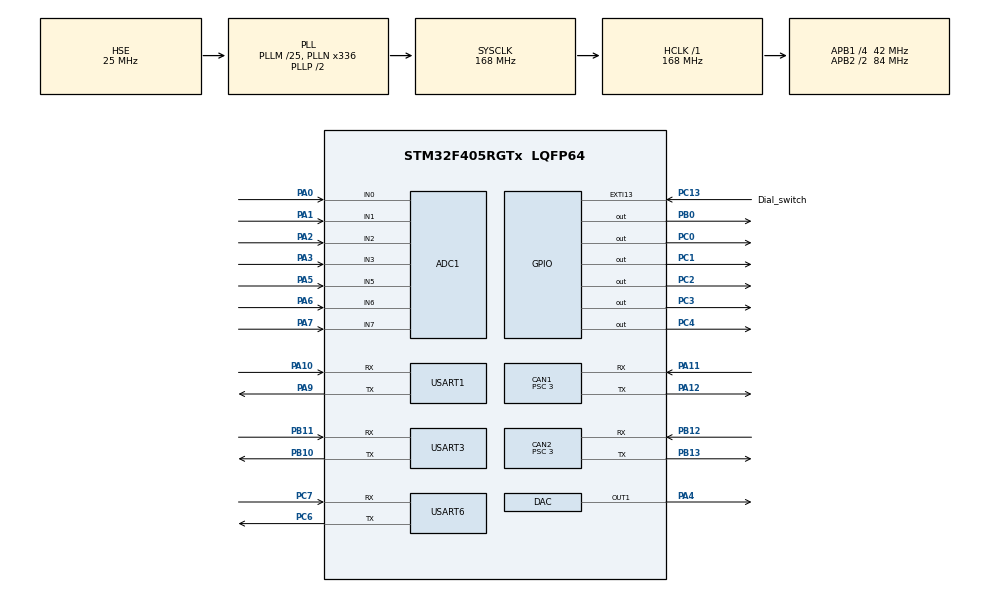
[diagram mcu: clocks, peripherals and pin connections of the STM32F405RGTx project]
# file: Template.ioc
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ADC1.Channel-0\#ChannelRegularConversion=ADC_CHANNEL_0
ADC1.Channel-1\#ChannelRegularConversion=ADC_CHANNEL_1
ADC1.Channel-2\#ChannelRegularConversion=ADC_CHANNEL_2
ADC1.Channel-3\#ChannelRegularConversion=ADC_CHANNEL_3
ADC1.Channel-4\#ChannelRegularConversion=ADC_CHANNEL_5
ADC1.Channel-5\#ChannelRegularConversion=ADC_CHANNEL_6
ADC1.Channel-6\#ChannelRegularConversion=ADC_CHANNEL_7
ADC1.ContinuousConvMode=ENABLE
ADC1.DMAContinuousRequests=ENABLE
ADC1.NbrOfConversion=7
ADC1.NbrOfConversionFlag=1
ADC1.Rank-0\#ChannelRegularConversion=1
ADC1.Rank-1\#ChannelRegularConversion=2
ADC1.Rank-2\#ChannelRegularConversion=3
ADC1.Rank-3\#ChannelRegularConversion=4
ADC1.Rank-4\#ChannelRegularConversion=5
ADC1.Rank-5\#ChannelRegularConversion=6
ADC1.Rank-6\#ChannelRegularConversion=7
ADC1.SamplingTime-0\#ChannelRegularConversion=ADC_SAMPLETIME_3CYCLES
ADC1.SamplingTime-1\#ChannelRegularConversion=ADC_SAMPLETIME_3CYCLES
ADC1.SamplingTime-2\#ChannelRegularConversion=ADC_SAMPLETIME_3CYCLES
ADC1.SamplingTime-3\#ChannelRegularConversion=ADC_SAMPLETIME_3CYCLES
ADC1.SamplingTime-4\#ChannelRegularConversion=ADC_SAMPLETIME_3CYCLES
ADC1.SamplingTime-5\#ChannelRegularConversion=ADC_SAMPLETIME_3CYCLES
ADC1.SamplingTime-6\#ChannelRegularConversion=ADC_SAMPLETIME_3CYCLES
ADC1.ScanConvMode=ENABLE
ADC1.master=1
CAN1.ABOM=ENABLE
CAN1.BS1=CAN_BS1_9TQ
CAN1.BS2=CAN_BS2_4TQ
CAN1.CalculateTimeQuantum=71.42857142857143
CAN1.NART=ENABLE
CAN1.Prescaler=3
CAN2.ABOM=ENABLE
CAN2.BS1=CAN_BS1_9TQ
CAN2.BS2=CAN_BS2_4TQ
CAN2.CalculateTimeQuantum=71.42857142857143
CAN2.NART=ENABLE
CAN2.Prescaler=3
DAC.DAC_OutputBuffer=DAC_OUTPUTBUFFER_DISABLE
Dma.ADC1.6.Direction=DMA_PERIPH_TO_MEMORY
Dma.ADC1.6.FIFOMode=DMA_FIFOMODE_DISABLE
Dma.ADC1.6.Instance=DMA2_Stream0
Dma.ADC1.6.MemDataAlignment=DMA_MDATAALIGN_WORD
Dma.ADC1.6.MemInc=DMA_MINC_ENABLE
Dma.ADC1.6.Mode=DMA_CIRCULAR
Dma.ADC1.6.PeriphDataAlignment=DMA_PDATAALIGN_WORD
Dma.ADC1.6.PeriphInc=DMA_PINC_DISABLE
Dma.ADC1.6.Priority=DMA_PRIORITY_HIGH
Dma.DAC1.7.Direction=DMA_MEMORY_TO_PERIPH
Dma.DAC1.7.FIFOMode=DMA_FIFOMODE_DISABLE
Dma.DAC1.7.Instance=DMA1_Stream5
Dma.DAC1.7.MemDataAlignment=DMA_MDATAALIGN_HALFWORD
Dma.DAC1.7.MemInc=DMA_MINC_ENABLE
Dma.DAC1.7.Mode=DMA_NORMAL
Dma.DAC1.7.PeriphDataAlignment=DMA_PDATAALIGN_HALFWORD
Dma.DAC1.7.PeriphInc=DMA_PINC_DISABLE
Dma.DAC1.7.Priority=DMA_PRIORITY_HIGH
Dma.Request0=USART1_RX
Dma.Request1=USART1_TX
Dma.Request2=USART3_RX
Dma.Request3=USART3_TX
Dma.Request4=USART6_RX
Dma.Request5=USART6_TX
Dma.Request6=ADC1
Dma.Request7=DAC1
Dma.USART1_RX.0.Direction=DMA_PERIPH_TO_MEMORY
Dma.USART1_RX.0.FIFOMode=DMA_FIFOMODE_DISABLE
Dma.USART1_RX.0.Instance=DMA2_Stream2
Dma.USART1_RX.0.MemDataAlignment=DMA_MDATAALIGN_BYTE
Dma.USART1_RX.0.MemInc=DMA_MINC_ENABLE
Dma.USART1_RX.0.Mode=DMA_NORMAL
Dma.USART1_RX.0.PeriphDataAlignment=DMA_PDATAALIGN_BYTE
Dma.USART1_RX.0.PeriphInc=DMA_PINC_DISABLE
Dma.USART1_RX.0.Priority=DMA_PRIORITY_LOW
Dma.USART1_TX.1.Direction=DMA_MEMORY_TO_PERIPH
Dma.USART1_TX.1.FIFOMode=DMA_FIFOMODE_DISABLE
Dma.USART1_TX.1.Instance=DMA2_Stream7
Dma.USART1_TX.1.MemDataAlignment=DMA_MDATAALIGN_BYTE
Dma.USART1_TX.1.MemInc=DMA_MINC_ENABLE
Dma.USART1_TX.1.Mode=DMA_NORMAL
Dma.USART1_TX.1.PeriphDataAlignment=DMA_PDATAALIGN_BYTE
Dma.USART1_TX.1.PeriphInc=DMA_PINC_DISABLE
Dma.USART1_TX.1.Priority=DMA_PRIORITY_LOW
Dma.USART3_RX.2.Direction=DMA_PERIPH_TO_MEMORY
Dma.USART3_RX.2.FIFOMode=DMA_FIFOMODE_DISABLE
Dma.USART3_RX.2.Instance=DMA1_Stream1
Dma.USART3_RX.2.MemDataAlignment=DMA_MDATAALIGN_BYTE
Dma.USART3_RX.2.MemInc=DMA_MINC_ENABLE
Dma.USART3_RX.2.Mode=DMA_NORMAL
Dma.USART3_RX.2.PeriphDataAlignment=DMA_PDATAALIGN_BYTE
Dma.USART3_RX.2.PeriphInc=DMA_PINC_DISABLE
Dma.USART3_RX.2.Priority=DMA_PRIORITY_LOW
Dma.USART3_TX.3.Direction=DMA_MEMORY_TO_PERIPH
Dma.USART3_TX.3.FIFOMode=DMA_FIFOMODE_DISABLE
Dma.USART3_TX.3.Instance=DMA1_Stream3
Dma.USART3_TX.3.MemDataAlignment=DMA_MDATAALIGN_BYTE
Dma.USART3_TX.3.MemInc=DMA_MINC_ENABLE
Dma.USART3_TX.3.Mode=DMA_NORMAL
Dma.USART3_TX.3.PeriphDataAlignment=DMA_PDATAALIGN_BYTE
Dma.USART3_TX.3.PeriphInc=DMA_PINC_DISABLE
Dma.USART3_TX.3.Priority=DMA_PRIORITY_LOW
Dma.USART6_RX.4.Direction=DMA_PERIPH_TO_MEMORY
Dma.USART6_RX.4.FIFOMode=DMA_FIFOMODE_DISABLE
Dma.USART6_RX.4.Instance=DMA2_Stream1
Dma.USART6_RX.4.MemDataAlignment=DMA_MDATAALIGN_BYTE
Dma.USART6_RX.4.MemInc=DMA_MINC_ENABLE
Dma.USART6_RX.4.Mode=DMA_NORMAL
Dma.USART6_RX.4.PeriphDataAlignment=DMA_PDATAALIGN_BYTE
Dma.USART6_RX.4.PeriphInc=DMA_PINC_DISABLE
Dma.USART6_RX.4.Priority=DMA_PRIORITY_LOW
Dma.USART6_TX.5.Direction=DMA_MEMORY_TO_PERIPH
Dma.USART6_TX.5.FIFOMode=DMA_FIFOMODE_DISABLE
Dma.USART6_TX.5.Instance=DMA2_Stream6
Dma.USART6_TX.5.MemDataAlignment=DMA_MDATAALIGN_BYTE
Dma.USART6_TX.5.MemInc=DMA_MINC_ENABLE
Dma.USART6_TX.5.Mode=DMA_NORMAL
Dma.USART6_TX.5.PeriphDataAlignment=DMA_PDATAALIGN_BYTE
Dma.USART6_TX.5.PeriphInc=DMA_PINC_DISABLE
Dma.USART6_TX.5.Priority=DMA_PRIORITY_LOW
FREERTOS.INCLUDE_vTaskDelayUntil=1
FREERTOS.Tasks01=defaultTask,0,128,StartDefaultTask,Default,NULL
Mcu.Family=STM32F4
Mcu.Name=STM32F405RGTx
Mcu.Package=LQFP64
NVIC.ADC_IRQn=true\:5\:0\:false\:false\:true\:true\:true\:true
NVIC.CAN1_RX0_IRQn=true\:5\:0\:false\:false\:true\:true\:true\:true
NVIC.CAN1_RX1_IRQn=true\:5\:0\:false\:false\:true\:true\:true\:true
NVIC.CAN2_RX0_IRQn=true\:5\:0\:false\:false\:true\:true\:true\:true
NVIC.CAN2_RX1_IRQn=true\:5\:0\:false\:false\:true\:true\:true\:true
NVIC.CAN2_SCE_IRQn=true\:5\:0\:false\:false\:true\:true\:true\:true
NVIC.CAN2_TX_IRQn=true\:5\:0\:false\:false\:true\:true\:true\:true
NVIC.DMA1_Stream1_IRQn=true\:5\:0\:false\:false\:true\:true\:false\:true
NVIC.DMA1_Stream3_IRQn=true\:5\:0\:false\:false\:true\:true\:false\:true
NVIC.DMA1_Stream5_IRQn=true\:5\:0\:false\:false\:true\:true\:false\:true
NVIC.DMA2_Stream0_IRQn=true\:5\:0\:false\:false\:true\:true\:false\:true
NVIC.DMA2_Stream1_IRQn=true\:5\:0\:false\:false\:true\:true\:false\:true
NVIC.DMA2_Stream2_IRQn=true\:5\:0\:false\:false\:true\:true\:false\:true
NVIC.DMA2_Stream6_IRQn=true\:5\:0\:false\:false\:true\:true\:false\:true
NVIC.DMA2_Stream7_IRQn=true\:5\:0\:false\:false\:true\:true\:false\:true
NVIC.EXTI15_10_IRQn=true\:5\:0\:false\:false\:true\:true\:true\:true
NVIC.PriorityGroup=NVIC_PRIORITYGROUP_4
NVIC.TIM4_IRQn=true\:5\:0\:false\:false\:true\:true\:true\:true
NVIC.TIM5_IRQn=true\:0\:0\:false\:false\:true\:false\:false\:true
NVIC.TIM6_DAC_IRQn=true\:5\:0\:false\:false\:true\:true\:true\:true
NVIC.TimeBase=TIM5_IRQn
NVIC.TimeBaseIP=TIM5
NVIC.USART1_IRQn=true\:5\:0\:false\:false\:true\:true\:true\:true
NVIC.USART6_IRQn=true\:5\:0\:false\:false\:true\:true\:true\:true
PA0-WKUP.Signal=ADCx_IN0
PA1.Signal=ADCx_IN1
PA10.Mode=Asynchronous
PA10.Signal=USART1_RX
PA11.Mode=Master
PA11.Signal=CAN1_RX
PA12.Mode=Master
PA12.Signal=CAN1_TX
PA13.Mode=Serial_Wire
PA13.Signal=SYS_JTMS-SWDIO
PA14.Mode=Serial_Wire
PA14.Signal=SYS_JTCK-SWCLK
PA2.Signal=ADCx_IN2
PA3.Signal=ADCx_IN3
PA4.Signal=COMP_DAC1_group
PA5.Signal=ADCx_IN5
PA6.Signal=ADCx_IN6
PA7.Signal=ADCx_IN7
PA9.Mode=Asynchronous
PA9.Signal=USART1_TX
PB0.GPIO_ModeDefaultOutputPP=GPIO_MODE_OUTPUT_OD
PB0.PinState=GPIO_PIN_RESET
PB0.Signal=GPIO_Output
PB10.Mode=Asynchronous
PB10.Signal=USART3_TX
PB11.Mode=Asynchronous
PB11.Signal=USART3_RX
PB12.Mode=Slave
PB12.Signal=CAN2_RX
PB13.Mode=Slave
PB13.Signal=CAN2_TX
PC0.GPIO_Speed=GPIO_SPEED_FREQ_HIGH
PC0.PinState=GPIO_PIN_RESET
PC0.Signal=GPIO_Output
PC1.GPIO_Speed=GPIO_SPEED_FREQ_HIGH
PC1.Signal=GPIO_Output
PC13-ANTI_TAMP.GPIO_Label=Dial_switch
PC13-ANTI_TAMP.GPIO_ModeDefaultEXTI=GPIO_MODE_IT_FALLING
PC13-ANTI_TAMP.GPIO_PuPd=GPIO_PULLUP
PC13-ANTI_TAMP.Signal=GPXTI13
PC2.GPIO_Speed=GPIO_SPEED_FREQ_HIGH
PC2.Signal=GPIO_Output
PC3.GPIO_Speed=GPIO_SPEED_FREQ_HIGH
PC3.Signal=GPIO_Output
PC4.GPIO_Speed=GPIO_SPEED_FREQ_HIGH
PC4.Signal=GPIO_Output
PC6.Mode=Asynchronous
PC6.Signal=USART6_TX
PC7.Mode=Asynchronous
PC7.Signal=USART6_RX
PH0-OSC_IN.Mode=HSE-External-Oscillator
PH0-OSC_IN.Signal=RCC_OSC_IN
PH1-OSC_OUT.Mode=HSE-External-Oscillator
PH1-OSC_OUT.Signal=RCC_OSC_OUT
ProjectManager.HeapSize=0x200
ProjectManager.StackSize=0x400
ProjectManager.TargetToolchain=MDK-ARM V5.27
RCC.48MHZClocksFreq_Value=84000000
RCC.AHBFreq_Value=168000000
RCC.APB1CLKDivider=RCC_HCLK_DIV4
RCC.APB1Freq_Value=42000000
RCC.APB1TimFreq_Value=84000000
RCC.APB2CLKDivider=RCC_HCLK_DIV2
RCC.APB2Freq_Value=84000000
RCC.APB2TimFreq_Value=168000000
RCC.CortexFreq_Value=168000000
RCC.HCLKFreq_Value=168000000
RCC.HSE_VALUE=25000000
RCC.HSI_VALUE=16000000
RCC.LSE_VALUE=32768
RCC.PLLM=25
RCC.PLLN=336
RCC.PLLSourceVirtual=RCC_PLLSOURCE_HSE
RCC.SYSCLKFreq_VALUE=168000000
RCC.SYSCLKSource=RCC_SYSCLKSOURCE_PLLCLK
RCC.VCOOutputFreq_Value=336000000
SH.ADCx_IN0.0=ADC1_IN0,IN0
SH.ADCx_IN1.0=ADC1_IN1,IN1
SH.ADCx_IN2.0=ADC1_IN2,IN2
SH.ADCx_IN3.0=ADC1_IN3,IN3
SH.ADCx_IN5.0=ADC1_IN5,IN5
SH.ADCx_IN6.0=ADC1_IN6,IN6
SH.ADCx_IN7.0=ADC1_IN7,IN7
SH.COMP_DAC1_group.0=DAC_OUT1,DAC_OUT1
TIM4.Period=65535
TIM4.Prescaler=83
USART1.VirtualMode=VM_ASYNC
USART3.VirtualMode=VM_ASYNC
USART6.VirtualMode=VM_ASYNC
VP_FREERTOS_VS_CMSIS_V1.Mode=CMSIS_V1
VP_SYS_VS_tim5.Mode=TIM5
VP_TIM4_VS_ClockSourceINT.Mode=Internal
board=custom

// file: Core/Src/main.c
/* USER CODE BEGIN Header */
/**
  ******************************************************************************
  * @file           : main.c
  * @brief          : Main program body
  ******************************************************************************
  * @attention
  *
  * <h2><center>&copy; Copyright (c) 2019 STMicroelectronics.
  * All rights reserved.</center></h2>
  *
  * This software component is licensed by ST under Ultimate Liberty license
  * SLA0044, the "License"; You may not use this file except in compliance with
  * the License. You may obtain a copy of the License at:
  *                             www.st.com/SLA0044
  *
  ******************************************************************************
  */
/* USER CODE END Header */

#include "main.h"
#include "cmsis_os.h"

/* USER CODE BEGIN Includes */
#include "System_Config.h"
#include "Drivers/Components/drv_timer.h"
/* USER CODE END Includes */

ADC_HandleTypeDef hadc1;
DMA_HandleTypeDef hdma_adc1;

CAN_HandleTypeDef hcan1;
CAN_HandleTypeDef hcan2;

DAC_HandleTypeDef hdac;
DMA_HandleTypeDef hdma_dac1;

TIM_HandleTypeDef htim4;

UART_HandleTypeDef huart1;
UART_HandleTypeDef huart3;
UART_HandleTypeDef huart6;
DMA_HandleTypeDef hdma_usart1_rx;
DMA_HandleTypeDef hdma_usart1_tx;
DMA_HandleTypeDef hdma_usart3_rx;
DMA_HandleTypeDef hdma_usart3_tx;
DMA_HandleTypeDef hdma_usart6_rx;
DMA_HandleTypeDef hdma_usart6_tx;

osThreadId defaultTaskHandle;

void SystemClock_Config(void);
static void MX_GPIO_Init(void);
static void MX_DMA_Init(void);
static void MX_CAN1_Init(void);
static void MX_CAN2_Init(void);
static void MX_TIM4_Init(void);
static void MX_USART1_UART_Init(void);
static void MX_USART3_UART_Init(void);
static void MX_USART6_UART_Init(void);
static void MX_ADC1_Init(void);
static void MX_DAC_Init(void);
void StartDefaultTask(void const * argument);

int main(void)
{

  /* MCU Configuration--------------------------------------------------------*/

  /* Reset of all peripherals, Initializes the Flash interface and the Systick. */
  HAL_Init();

  /* Configure the system clock */
  SystemClock_Config();

  /* Initialize all configured peripherals */
  MX_GPIO_Init();
  MX_DMA_Init();
  MX_CAN1_Init();
  MX_CAN2_Init();
  MX_TIM4_Init();
  MX_USART1_UART_Init();
  MX_USART3_UART_Init();
  MX_USART6_UART_Init();
  MX_ADC1_Init();
  MX_DAC_Init();
  /* USER CODE BEGIN 2 */
  System_Resource_Init();
  System_Tasks_Init();
  /* USER CODE END 2 */

  /* Create the thread(s) */
  /* definition and creation of defaultTask */
  osThreadDef(defaultTask, StartDefaultTask, osPriorityNormal, 0, 128);
  defaultTaskHandle = osThreadCreate(osThread(defaultTask), NULL);

  /* Start scheduler */
  osKernelStart();

  /* We should never get here as control is now taken by the scheduler */

  /* Infinite loop */
  while (1)
  {

  }
}

void SystemClock_Config(void)
{
  RCC_OscInitTypeDef RCC_OscInitStruct = {0};
  RCC_ClkInitTypeDef RCC_ClkInitStruct = {0};

  /** Configure the main internal regulator output voltage
  */
  __HAL_RCC_PWR_CLK_ENABLE();
  __HAL_PWR_VOLTAGESCALING_CONFIG(PWR_REGULATOR_VOLTAGE_SCALE1);
  /** Initializes the CPU, AHB and APB busses clocks
  */
  RCC_OscInitStruct.OscillatorType = RCC_OSCILLATORTYPE_HSE;
  RCC_OscInitStruct.HSEState = RCC_HSE_ON;
  RCC_OscInitStruct.PLL.PLLState = RCC_PLL_ON;
  RCC_OscInitStruct.PLL.PLLSource = RCC_PLLSOURCE_HSE;
  RCC_OscInitStruct.PLL.PLLM = 25;
  RCC_OscInitStruct.PLL.PLLN = 336;
  RCC_OscInitStruct.PLL.PLLP = RCC_PLLP_DIV2;
  RCC_OscInitStruct.PLL.PLLQ = 4;
  if (HAL_RCC_OscConfig(&RCC_OscInitStruct) != HAL_OK)
  {
    Error_Handler();
  }
  /** Initializes the CPU, AHB and APB busses clocks
  */
  RCC_ClkInitStruct.ClockType = RCC_CLOCKTYPE_HCLK|RCC_CLOCKTYPE_SYSCLK
                              |RCC_CLOCKTYPE_PCLK1|RCC_CLOCKTYPE_PCLK2;
  RCC_ClkInitStruct.SYSCLKSource = RCC_SYSCLKSOURCE_PLLCLK;
  RCC_ClkInitStruct.AHBCLKDivider = RCC_SYSCLK_DIV1;
  RCC_ClkInitStruct.APB1CLKDivider = RCC_HCLK_DIV4;
  RCC_ClkInitStruct.APB2CLKDivider = RCC_HCLK_DIV2;

  if (HAL_RCC_ClockConfig(&RCC_ClkInitStruct, FLASH_LATENCY_5) != HAL_OK)
  {
    Error_Handler();
  }
}

static void MX_ADC1_Init(void)
{

  ADC_ChannelConfTypeDef sConfig = {0};

  /** Configure the global features of the ADC (Clock, Resolution, Data Alignment and number of conversion)
  */
  hadc1.Instance = ADC1;
  hadc1.Init.ClockPrescaler = ADC_CLOCK_SYNC_PCLK_DIV4;
  hadc1.Init.Resolution = ADC_RESOLUTION_12B;
  hadc1.Init.ScanConvMode = ENABLE;
  hadc1.Init.ContinuousConvMode = ENABLE;
  hadc1.Init.DiscontinuousConvMode = DISABLE;
  hadc1.Init.ExternalTrigConvEdge = ADC_EXTERNALTRIGCONVEDGE_NONE;
  hadc1.Init.ExternalTrigConv = ADC_SOFTWARE_START;
  hadc1.Init.DataAlign = ADC_DATAALIGN_RIGHT;
  hadc1.Init.NbrOfConversion = 7;
  hadc1.Init.DMAContinuousRequests = ENABLE;
  hadc1.Init.EOCSelection = ADC_EOC_SINGLE_CONV;
  if (HAL_ADC_Init(&hadc1) != HAL_OK)
  {
    Error_Handler();
  }
  /** Configure for the selected ADC regular channel its corresponding rank in the sequencer and its sample time.
  */
  sConfig.Channel = ADC_CHANNEL_0;
  sConfig.Rank = 1;
  sConfig.SamplingTime = ADC_SAMPLETIME_3CYCLES;
  if (HAL_ADC_ConfigChannel(&hadc1, &sConfig) != HAL_OK)
  {
    Error_Handler();
  }
  /** Configure for the selected ADC regular channel its corresponding rank in the sequencer and its sample time.
  */
  sConfig.Channel = ADC_CHANNEL_1;
  sConfig.Rank = 2;
  if (HAL_ADC_ConfigChannel(&hadc1, &sConfig) != HAL_OK)
  {
    Error_Handler();
  }
  /** Configure for the selected ADC regular channel its corresponding rank in the sequencer and its sample time.
  */
  sConfig.Channel = ADC_CHANNEL_2;
  sConfig.Rank = 3;
  if (HAL_ADC_ConfigChannel(&hadc1, &sConfig) != HAL_OK)
  {
    Error_Handler();
  }
  /** Configure for the selected ADC regular channel its corresponding rank in the sequencer and its sample time.
  */
  sConfig.Channel = ADC_CHANNEL_3;
  sConfig.Rank = 4;
  if (HAL_ADC_ConfigChannel(&hadc1, &sConfig) != HAL_OK)
  {
    Error_Handler();
  }
  /** Configure for the selected ADC regular channel its corresponding rank in the sequencer and its sample time.
  */
  sConfig.Channel = ADC_CHANNEL_5;
  sConfig.Rank = 5;
  if (HAL_ADC_ConfigChannel(&hadc1, &sConfig) != HAL_OK)
  {
    Error_Handler();
  }
  /** Configure for the selected ADC regular channel its corresponding rank in the sequencer and its sample time.
  */
  sConfig.Channel = ADC_CHANNEL_6;
  sConfig.Rank = 6;
  if (HAL_ADC_ConfigChannel(&hadc1, &sConfig) != HAL_OK)
  {
    Error_Handler();
  }
  /** Configure for the selected ADC regular channel its corresponding rank in the sequencer and its sample time.
  */
  sConfig.Channel = ADC_CHANNEL_7;
  sConfig.Rank = 7;
  if (HAL_ADC_ConfigChannel(&hadc1, &sConfig) != HAL_OK)
  {
    Error_Handler();
  }

}

static void MX_CAN1_Init(void)
{

  hcan1.Instance = CAN1;
  hcan1.Init.Prescaler = 3;
  hcan1.Init.Mode = CAN_MODE_NORMAL;
  hcan1.Init.SyncJumpWidth = CAN_SJW_1TQ;
  hcan1.Init.TimeSeg1 = CAN_BS1_9TQ;
  hcan1.Init.TimeSeg2 = CAN_BS2_4TQ;
  hcan1.Init.TimeTriggeredMode = DISABLE;
  hcan1.Init.AutoBusOff = ENABLE;
  hcan1.Init.AutoWakeUp = DISABLE;
  hcan1.Init.AutoRetransmission = ENABLE;
  hcan1.Init.ReceiveFifoLocked = DISABLE;
  hcan1.Init.TransmitFifoPriority = DISABLE;
  if (HAL_CAN_Init(&hcan1) != HAL_OK)
  {
    Error_Handler();
  }

}

static void MX_CAN2_Init(void)
{

  hcan2.Instance = CAN2;
  hcan2.Init.Prescaler = 3;
  hcan2.Init.Mode = CAN_MODE_NORMAL;
  hcan2.Init.SyncJumpWidth = CAN_SJW_1TQ;
  hcan2.Init.TimeSeg1 = CAN_BS1_9TQ;
  hcan2.Init.TimeSeg2 = CAN_BS2_4TQ;
  hcan2.Init.TimeTriggeredMode = DISABLE;
  hcan2.Init.AutoBusOff = ENABLE;
  hcan2.Init.AutoWakeUp = DISABLE;
  hcan2.Init.AutoRetransmission = ENABLE;
  hcan2.Init.ReceiveFifoLocked = DISABLE;
  hcan2.Init.TransmitFifoPriority = DISABLE;
  if (HAL_CAN_Init(&hcan2) != HAL_OK)
  {
    Error_Handler();
  }

}

static void MX_DAC_Init(void)
{

  DAC_ChannelConfTypeDef sConfig = {0};

  /** DAC Initialization
  */
  hdac.Instance = DAC;
  if (HAL_DAC_Init(&hdac) != HAL_OK)
  {
    Error_Handler();
  }
  /** DAC channel OUT1 config
  */
  sConfig.DAC_Trigger = DAC_TRIGGER_NONE;
  sConfig.DAC_OutputBuffer = DAC_OUTPUTBUFFER_DISABLE;
  if (HAL_DAC_ConfigChannel(&hdac, &sConfig, DAC_CHANNEL_1) != HAL_OK)
  {
    Error_Handler();
  }

}

static void MX_TIM4_Init(void)
{

  TIM_ClockConfigTypeDef sClockSourceConfig = {0};
  TIM_MasterConfigTypeDef sMasterConfig = {0};

  htim4.Instance = TIM4;
  htim4.Init.Prescaler = 83;
  htim4.Init.CounterMode = TIM_COUNTERMODE_UP;
  htim4.Init.Period = 65535;
  htim4.Init.ClockDivision = TIM_CLOCKDIVISION_DIV1;
  htim4.Init.AutoReloadPreload = TIM_AUTORELOAD_PRELOAD_DISABLE;
  if (HAL_TIM_Base_Init(&htim4) != HAL_OK)
  {
    Error_Handler();
  }
  sClockSourceConfig.ClockSource = TIM_CLOCKSOURCE_INTERNAL;
  if (HAL_TIM_ConfigClockSource(&htim4, &sClockSourceConfig) != HAL_OK)
  {
    Error_Handler();
  }
  sMasterConfig.MasterOutputTrigger = TIM_TRGO_RESET;
  sMasterConfig.MasterSlaveMode = TIM_MASTERSLAVEMODE_DISABLE;
  if (HAL_TIMEx_MasterConfigSynchronization(&htim4, &sMasterConfig) != HAL_OK)
  {
    Error_Handler();
  }

}

static void MX_USART1_UART_Init(void)
{

  huart1.Instance = USART1;
  huart1.Init.BaudRate = 115200;
  huart1.Init.WordLength = UART_WORDLENGTH_8B;
  huart1.Init.StopBits = UART_STOPBITS_1;
  huart1.Init.Parity = UART_PARITY_NONE;
  huart1.Init.Mode = UART_MODE_TX_RX;
  huart1.Init.HwFlowCtl = UART_HWCONTROL_NONE;
  huart1.Init.OverSampling = UART_OVERSAMPLING_16;
  if (HAL_UART_Init(&huart1) != HAL_OK)
  {
    Error_Handler();
  }

}

static void MX_USART3_UART_Init(void)
{

  huart3.Instance = USART3;
  huart3.Init.BaudRate = 115200;
  huart3.Init.WordLength = UART_WORDLENGTH_8B;
  huart3.Init.StopBits = UART_STOPBITS_1;
  huart3.Init.Parity = UART_PARITY_NONE;
  huart3.Init.Mode = UART_MODE_TX_RX;
  huart3.Init.HwFlowCtl = UART_HWCONTROL_NONE;
  huart3.Init.OverSampling = UART_OVERSAMPLING_16;
  if (HAL_UART_Init(&huart3) != HAL_OK)
  {
    Error_Handler();
  }

}

static void MX_USART6_UART_Init(void)
{

  huart6.Instance = USART6;
  huart6.Init.BaudRate = 115200;
  huart6.Init.WordLength = UART_WORDLENGTH_8B;
  huart6.Init.StopBits = UART_STOPBITS_1;
  huart6.Init.Parity = UART_PARITY_NONE;
  huart6.Init.Mode = UART_MODE_TX_RX;
  huart6.Init.HwFlowCtl = UART_HWCONTROL_NONE;
  huart6.Init.OverSampling = UART_OVERSAMPLING_16;
  if (HAL_UART_Init(&huart6) != HAL_OK)
  {
    Error_Handler();
  }

}

static void MX_DMA_Init(void)
{

  /* DMA controller clock enable */
  __HAL_RCC_DMA2_CLK_ENABLE();
  __HAL_RCC_DMA1_CLK_ENABLE();

  /* DMA interrupt init */
  /* DMA1_Stream1_IRQn interrupt configuration */
  HAL_NVIC_SetPriority(DMA1_Stream1_IRQn, 5, 0);
  HAL_NVIC_EnableIRQ(DMA1_Stream1_IRQn);
  /* DMA1_Stream3_IRQn interrupt configuration */
  HAL_NVIC_SetPriority(DMA1_Stream3_IRQn, 5, 0);
  HAL_NVIC_EnableIRQ(DMA1_Stream3_IRQn);
  /* DMA1_Stream5_IRQn interrupt configuration */
  HAL_NVIC_SetPriority(DMA1_Stream5_IRQn, 5, 0);
  HAL_NVIC_EnableIRQ(DMA1_Stream5_IRQn);
  /* DMA2_Stream0_IRQn interrupt configuration */
  HAL_NVIC_SetPriority(DMA2_Stream0_IRQn, 5, 0);
  HAL_NVIC_EnableIRQ(DMA2_Stream0_IRQn);
  /* DMA2_Stream1_IRQn interrupt configuration */
  HAL_NVIC_SetPriority(DMA2_Stream1_IRQn, 5, 0);
  HAL_NVIC_EnableIRQ(DMA2_Stream1_IRQn);
  /* DMA2_Stream2_IRQn interrupt configuration */
  HAL_NVIC_SetPriority(DMA2_Stream2_IRQn, 5, 0);
  HAL_NVIC_EnableIRQ(DMA2_Stream2_IRQn);
  /* DMA2_Stream6_IRQn interrupt configuration */
  HAL_NVIC_SetPriority(DMA2_Stream6_IRQn, 5, 0);
  HAL_NVIC_EnableIRQ(DMA2_Stream6_IRQn);
  /* DMA2_Stream7_IRQn interrupt configuration */
  HAL_NVIC_SetPriority(DMA2_Stream7_IRQn, 5, 0);
  HAL_NVIC_EnableIRQ(DMA2_Stream7_IRQn);

}

static void MX_GPIO_Init(void)
{
  GPIO_InitTypeDef GPIO_InitStruct = {0};

  /* GPIO Ports Clock Enable */
  __HAL_RCC_GPIOC_CLK_ENABLE();
  __HAL_RCC_GPIOH_CLK_ENABLE();
  __HAL_RCC_GPIOA_CLK_ENABLE();
  __HAL_RCC_GPIOB_CLK_ENABLE();

  /*Configure GPIO pin Output Level */
  HAL_GPIO_WritePin(GPIOC, GPIO_PIN_0|GPIO_PIN_1|GPIO_PIN_2|GPIO_PIN_3
                          |GPIO_PIN_4, GPIO_PIN_RESET);

  /*Configure GPIO pin Output Level */
  HAL_GPIO_WritePin(GPIOB, GPIO_PIN_0, GPIO_PIN_RESET);

  /*Configure GPIO pin : Dial_switch_Pin */
  GPIO_InitStruct.Pin = Dial_switch_Pin;
  GPIO_InitStruct.Mode = GPIO_MODE_IT_FALLING;
  GPIO_InitStruct.Pull = GPIO_PULLUP;
  HAL_GPIO_Init(Dial_switch_GPIO_Port, &GPIO_InitStruct);

  /*Configure GPIO pins : PC0 PC1 PC2 PC3
                           PC4 */
  GPIO_InitStruct.Pin = GPIO_PIN_0|GPIO_PIN_1|GPIO_PIN_2|GPIO_PIN_3
                          |GPIO_PIN_4;
  GPIO_InitStruct.Mode = GPIO_MODE_OUTPUT_PP;
  GPIO_InitStruct.Pull = GPIO_NOPULL;
  GPIO_InitStruct.Speed = GPIO_SPEED_FREQ_HIGH;
  HAL_GPIO_Init(GPIOC, &GPIO_InitStruct);

  /*Configure GPIO pin : PB0 */
  GPIO_InitStruct.Pin = GPIO_PIN_0;
  GPIO_InitStruct.Mode = GPIO_MODE_OUTPUT_OD;
  GPIO_InitStruct.Pull = GPIO_NOPULL;
  GPIO_InitStruct.Speed = GPIO_SPEED_FREQ_LOW;
  HAL_GPIO_Init(GPIOB, &GPIO_InitStruct);

  /* EXTI interrupt init*/
  HAL_NVIC_SetPriority(EXTI15_10_IRQn, 5, 0);
  HAL_NVIC_EnableIRQ(EXTI15_10_IRQn);

}

/* USER CODE BEGIN 4 */
uint8_t Dial_switch=0;
void HAL_GPIO_EXTI_Callback(uint16_t GPIO_Pin)
{
	Dial_switch=1;
}
/* USER CODE END 4 */

void StartDefaultTask(void const * argument)
{
  /* USER CODE BEGIN 5 */

  /* Infinite loop */
  for(;;)
  {
//    System_Tasks_Init();
    /* Delete the default task. */
    osThreadTerminate (defaultTaskHandle);
  }
  /* USER CODE END 5 */
}

void HAL_TIM_PeriodElapsedCallback(TIM_HandleTypeDef *htim)
{
  /* USER CODE BEGIN Callback 0 */
  if (htim->Instance == TIM4) {
    Update_SystemTick();
  }
  /* USER CODE END Callback 0 */
  if (htim->Instance == TIM5) {
    HAL_IncTick();
  }
}

void Error_Handler(void)
{
}

/************************ (C) COPYRIGHT STMicroelectronics *****END OF FILE****/
